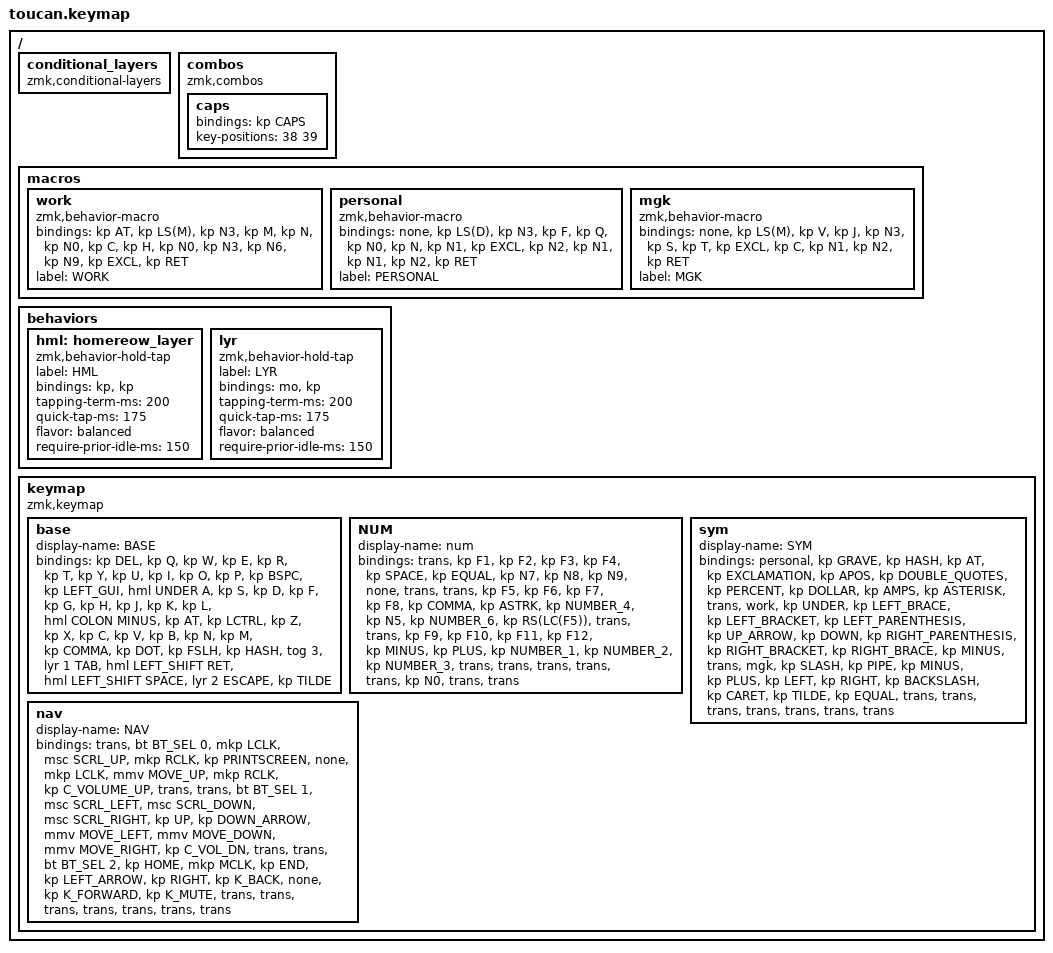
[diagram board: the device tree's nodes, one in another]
#include <behaviors.dtsi>
#include <dt-bindings/zmk/bt.h>
#include <dt-bindings/zmk/keys.h>
#include <dt-bindings/zmk/pointing.h>

#define BASE 0
#define NAV  1
#define SYM  2
#define ADJ  3

/ {
    conditional_layers { compatible = "zmk,conditional-layers"; };

    combos {
        compatible = "zmk,combos";

        caps {
            bindings = <&kp CAPS>;
            key-positions = <38 39>;
        };
    };

    macros {
        work: work {
            compatible = "zmk,behavior-macro";
            #binding-cells = <0>;
            bindings = <&kp AT &kp LS(M) &kp N3 &kp M &kp N &kp N0 &kp C &kp H &kp N0 &kp N3 &kp N6 &kp N9 &kp EXCL &kp RET>;
            label = "WORK";
        };

        personal: personal {
            compatible = "zmk,behavior-macro";
            #binding-cells = <0>;
            bindings = <&none &kp LS(D) &kp N3 &kp F &kp Q &kp N0 &kp N &kp N1 &kp EXCL &kp N2 &kp N1 &kp N1 &kp N2 &kp RET>;
            label = "PERSONAL";
        };

        mgk: mgk {
            compatible = "zmk,behavior-macro";
            #binding-cells = <0>;
            bindings = <&none &kp LS(M) &kp V &kp J &kp N3 &kp S &kp T &kp EXCL &kp C &kp N1 &kp N2 &kp RET>;
            label = "MGK";
        };
    };

    behaviors {
        hml: homereow_layer {
            compatible = "zmk,behavior-hold-tap";
            label = "HML";
            bindings = <&kp>, <&kp>;

            #binding-cells = <2>;
            tapping-term-ms = <200>;
            quick-tap-ms = <175>;
            flavor = "balanced";
            require-prior-idle-ms = <150>;
        };

        lyr: lyr {
            compatible = "zmk,behavior-hold-tap";
            label = "LYR";
            bindings = <&mo>, <&kp>;

            #binding-cells = <2>;
            tapping-term-ms = <200>;
            quick-tap-ms = <175>;
            flavor = "balanced";
            require-prior-idle-ms = <150>;
        };
    };

    keymap {
        compatible = "zmk,keymap";

        base {
            display-name = "BASE";
            bindings = <
&kp DEL  &kp Q  &kp W  &kp E  &kp R  &kp T  &kp Y  &kp U  &kp I  &kp O  &kp P  &kp BSPC  &kp LEFT_GUI  &hml UNDER A  &kp S  &kp D  &kp F  &kp G  &kp H  &kp J  &kp K  &kp L  &hml COLON MINUS  &kp AT  &kp LCTRL  &kp Z  &kp X  &kp C  &kp V  &kp B  &kp N  &kp M  &kp COMMA  &kp DOT  &kp FSLH  &kp HASH  &tog 3  &lyr 1 TAB  &hml LEFT_SHIFT RET  &hml LEFT_SHIFT SPACE  &lyr 2 ESCAPE  &kp TILDE
            >;
        };

        NUM {
            display-name = "num";
            bindings = <
&trans  &kp F1  &kp F2  &kp F3  &kp F4  &kp SPACE  &kp EQUAL  &kp N7  &kp N8  &kp N9  &none  &trans  &trans  &kp F5  &kp F6  &kp F7  &kp F8  &kp COMMA  &kp ASTRK  &kp NUMBER_4  &kp N5  &kp NUMBER_6  &kp RS(LC(F5))  &trans  &trans  &kp F9  &kp F10  &kp F11  &kp F12  &kp MINUS  &kp PLUS  &kp NUMBER_1  &kp NUMBER_2  &kp NUMBER_3  &trans  &trans  &trans  &trans  &trans  &kp N0  &trans  &trans
            >;
        };

        sym {
            display-name = "SYM";
            bindings = <
&personal  &kp GRAVE  &kp HASH  &kp AT  &kp EXCLAMATION  &kp APOS  &kp DOUBLE_QUOTES  &kp PERCENT  &kp DOLLAR  &kp AMPS  &kp ASTERISK  &trans  &work  &kp UNDER  &kp LEFT_BRACE  &kp LEFT_BRACKET  &kp LEFT_PARENTHESIS  &kp UP_ARROW  &kp DOWN  &kp RIGHT_PARENTHESIS  &kp RIGHT_BRACKET  &kp RIGHT_BRACE  &kp MINUS  &trans  &mgk  &kp SLASH  &kp PIPE  &kp MINUS  &kp PLUS  &kp LEFT  &kp RIGHT  &kp BACKSLASH  &kp CARET  &kp TILDE  &kp EQUAL  &trans  &trans  &trans  &trans  &trans  &trans  &trans
            >;
        };

        nav {
            display-name = "NAV";
            bindings = <
&trans  &bt BT_SEL 0  &mkp LCLK  &msc SCRL_UP  &mkp RCLK  &kp PRINTSCREEN  &none  &mkp LCLK  &mmv MOVE_UP  &mkp RCLK  &kp C_VOLUME_UP  &trans  &trans  &bt BT_SEL 1  &msc SCRL_LEFT  &msc SCRL_DOWN  &msc SCRL_RIGHT  &kp UP  &kp DOWN_ARROW  &mmv MOVE_LEFT  &mmv MOVE_DOWN  &mmv MOVE_RIGHT  &kp C_VOL_DN  &trans  &trans  &bt BT_SEL 2  &kp HOME  &mkp MCLK  &kp END  &kp LEFT_ARROW  &kp RIGHT  &kp K_BACK  &none  &kp K_FORWARD  &kp K_MUTE  &trans  &trans  &trans  &trans  &trans  &trans  &trans
            >;
        };
    };
};
